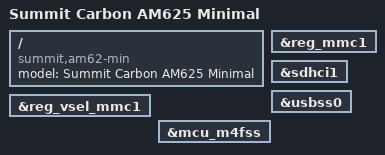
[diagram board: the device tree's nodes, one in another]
// SPDX-License-Identifier: GPL-2.0-or-later OR MIT
/*
 * Copyright 2024 Ezurio LLC
 *
 */

/dts-v1/;

#include "k3-am625-carbon-som.dtsi"

/ {
	model = "Summit Carbon AM625 Minimal";
	compatible = "summit,am62-min", "ti,am625";
};

&reg_vsel_mmc1 {
	status = "okay";
};

&reg_mmc1 {
	status = "okay";
};

&sdhci1 { /* SDIO_A uSD / M.2_SDIO */
	status = "okay";
};

&usbss0 {
	status = "okay";
};

&mcu_m4fss {
	status = "okay";
};
